AUTOSAR XML (schema 4-2-2)
package /AUTOSAR_ComM/SwcImplementations
  swc implementation ComM_Imp: programming-language=C, sw-version=10.0.0, vendor-id=6, behavior=ComM_Int
    code-descriptors:
      code ComM_Imp_Code: artifact-descriptors=autosar-engineering-object={short-label=Code, category=SWSRC}
    resource consumption ResourceConsumption_ResourceConsumption
package /AUTOSAR_ComM/SwComponentTypes
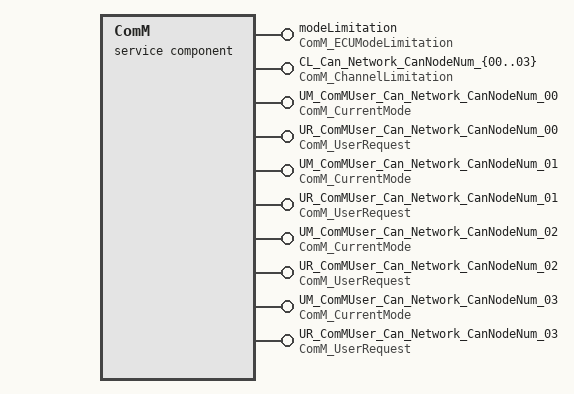
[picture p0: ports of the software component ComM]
  service sw component type ComM
    13 x provide port:
      modeLimitation: provided-interface=ComM_ECUModeLimitation
      CL_Can_Network_CanNodeNum_{00..03}: provided-interface=ComM_ChannelLimitation
      UM_ComMUser_Can_Network_CanNodeNum_00: mode-switch-sender-com-spec{mode-group=currentMode, queue-length=1}, provided-interface=ComM_CurrentMode
      UR_ComMUser_Can_Network_CanNodeNum_00: server-com-spec{operation=RequestComMode, queue-length=5}, provided-interface=ComM_UserRequest
      UM_ComMUser_Can_Network_CanNodeNum_01: mode-switch-sender-com-spec{mode-group=currentMode, queue-length=1}, provided-interface=ComM_CurrentMode
      UR_ComMUser_Can_Network_CanNodeNum_01: server-com-spec{operation=RequestComMode, queue-length=5}, provided-interface=ComM_UserRequest
      UM_ComMUser_Can_Network_CanNodeNum_02: mode-switch-sender-com-spec{mode-group=currentMode, queue-length=1}, provided-interface=ComM_CurrentMode
      UR_ComMUser_Can_Network_CanNodeNum_02: server-com-spec{operation=RequestComMode, queue-length=5}, provided-interface=ComM_UserRequest
      UM_ComMUser_Can_Network_CanNodeNum_03: mode-switch-sender-com-spec{mode-group=currentMode, queue-length=1}, provided-interface=ComM_CurrentMode
      UR_ComMUser_Can_Network_CanNodeNum_03: server-com-spec{operation=RequestComMode, queue-length=5}, provided-interface=ComM_UserRequest
    behavior ComM_Int: data-type-mapping=ComMModeMapping, handle-termination-and-restart=CAN-BE-TERMINATED-AND-RESTARTED
      28 x operation invoked event:
        OIE_UR_ComMUser_Can_Network_CanNodeNum_00_RequestComMode: start-on-event=RequestComMode, operation=UR_ComMUser_Can_Network_CanNodeNum_00.RequestComMode
        OIE_UR_ComMUser_Can_Network_CanNodeNum_00_GetRequestedComMode: start-on-event=GetRequestedComMode, operation=UR_ComMUser_Can_Network_CanNodeNum_00.GetRequestedComMode
        OIE_UR_ComMUser_Can_Network_CanNodeNum_00_GetCurrentComMode: start-on-event=GetCurrentComMode, operation=UR_ComMUser_Can_Network_CanNodeNum_00.GetCurrentComMode
        OIE_UR_ComMUser_Can_Network_CanNodeNum_00_GetMaxComMode: start-on-event=GetMaxComMode, operation=UR_ComMUser_Can_Network_CanNodeNum_00.GetMaxComMode
        OIE_UR_ComMUser_Can_Network_CanNodeNum_01_RequestComMode: start-on-event=RequestComMode, operation=UR_ComMUser_Can_Network_CanNodeNum_01.RequestComMode
        OIE_UR_ComMUser_Can_Network_CanNodeNum_01_GetRequestedComMode: start-on-event=GetRequestedComMode, operation=UR_ComMUser_Can_Network_CanNodeNum_01.GetRequestedComMode
        OIE_UR_ComMUser_Can_Network_CanNodeNum_01_GetCurrentComMode: start-on-event=GetCurrentComMode, operation=UR_ComMUser_Can_Network_CanNodeNum_01.GetCurrentComMode
        OIE_UR_ComMUser_Can_Network_CanNodeNum_01_GetMaxComMode: start-on-event=GetMaxComMode, operation=UR_ComMUser_Can_Network_CanNodeNum_01.GetMaxComMode
        OIE_UR_ComMUser_Can_Network_CanNodeNum_02_RequestComMode: start-on-event=RequestComMode, operation=UR_ComMUser_Can_Network_CanNodeNum_02.RequestComMode
        OIE_UR_ComMUser_Can_Network_CanNodeNum_02_GetRequestedComMode: start-on-event=GetRequestedComMode, operation=UR_ComMUser_Can_Network_CanNodeNum_02.GetRequestedComMode
        OIE_UR_ComMUser_Can_Network_CanNodeNum_02_GetCurrentComMode: start-on-event=GetCurrentComMode, operation=UR_ComMUser_Can_Network_CanNodeNum_02.GetCurrentComMode
        OIE_UR_ComMUser_Can_Network_CanNodeNum_02_GetMaxComMode: start-on-event=GetMaxComMode, operation=UR_ComMUser_Can_Network_CanNodeNum_02.GetMaxComMode
        OIE_UR_ComMUser_Can_Network_CanNodeNum_03_RequestComMode: start-on-event=RequestComMode, operation=UR_ComMUser_Can_Network_CanNodeNum_03.RequestComMode
        OIE_UR_ComMUser_Can_Network_CanNodeNum_03_GetRequestedComMode: start-on-event=GetRequestedComMode, operation=UR_ComMUser_Can_Network_CanNodeNum_03.GetRequestedComMode
        OIE_UR_ComMUser_Can_Network_CanNodeNum_03_GetCurrentComMode: start-on-event=GetCurrentComMode, operation=UR_ComMUser_Can_Network_CanNodeNum_03.GetCurrentComMode
        OIE_UR_ComMUser_Can_Network_CanNodeNum_03_GetMaxComMode: start-on-event=GetMaxComMode, operation=UR_ComMUser_Can_Network_CanNodeNum_03.GetMaxComMode
        OIE_ML_LimitECUToNoComMode: start-on-event=LimitECUToNoComMode, operation=modeLimitation.LimitECUToNoComMode
        OIE_ML_ReadInhibitCounter: start-on-event=ReadInhibitCounter, operation=modeLimitation.ReadInhibitCounter
        OIE_ML_ResetInhibitCounter: start-on-event=ResetInhibitCounter, operation=modeLimitation.ResetInhibitCounter
        OIE_ML_SetECUGroupClassification: start-on-event=SetECUGroupClassification, operation=modeLimitation.SetECUGroupClassification
        OIE_CL_Can_Network_CanNodeNum_00_LimitChannelToNoComMode: start-on-event=LimitChannelToNoComMode, operation=CL_Can_Network_CanNodeNum_00.LimitChannelToNoComMode
        OIE_CL_Can_Network_CanNodeNum_00_GetInhibitionStatus: start-on-event=GetInhibitionStatus, operation=CL_Can_Network_CanNodeNum_00.GetInhibitionStatus
        OIE_CL_Can_Network_CanNodeNum_01_LimitChannelToNoComMode: start-on-event=LimitChannelToNoComMode, operation=CL_Can_Network_CanNodeNum_01.LimitChannelToNoComMode
        OIE_CL_Can_Network_CanNodeNum_01_GetInhibitionStatus: start-on-event=GetInhibitionStatus, operation=CL_Can_Network_CanNodeNum_01.GetInhibitionStatus
        OIE_CL_Can_Network_CanNodeNum_02_LimitChannelToNoComMode: start-on-event=LimitChannelToNoComMode, operation=CL_Can_Network_CanNodeNum_02.LimitChannelToNoComMode
        OIE_CL_Can_Network_CanNodeNum_02_GetInhibitionStatus: start-on-event=GetInhibitionStatus, operation=CL_Can_Network_CanNodeNum_02.GetInhibitionStatus
        OIE_CL_Can_Network_CanNodeNum_03_LimitChannelToNoComMode: start-on-event=LimitChannelToNoComMode, operation=CL_Can_Network_CanNodeNum_03.LimitChannelToNoComMode
        OIE_CL_Can_Network_CanNodeNum_03_GetInhibitionStatus: start-on-event=GetInhibitionStatus, operation=CL_Can_Network_CanNodeNum_03.GetInhibitionStatus
      port-api-options:
        {enable-take-address=false, indirect-api=false, port-defined-argument-value{value=UR_ComMUser_Can_Network_CanNodeNum_00:0, value-type=ComM_UserHandleType}, port=UR_ComMUser_Can_Network_CanNodeNum_00}
        {enable-take-address=false, indirect-api=false, port-defined-argument-value{value=UR_ComMUser_Can_Network_CanNodeNum_01:1, value-type=ComM_UserHandleType}, port=UR_ComMUser_Can_Network_CanNodeNum_01}
        {enable-take-address=false, indirect-api=false, port-defined-argument-value{value=UR_ComMUser_Can_Network_CanNodeNum_02:2, value-type=ComM_UserHandleType}, port=UR_ComMUser_Can_Network_CanNodeNum_02}
        {enable-take-address=false, indirect-api=false, port-defined-argument-value{value=UR_ComMUser_Can_Network_CanNodeNum_03:3, value-type=ComM_UserHandleType}, port=UR_ComMUser_Can_Network_CanNodeNum_03}
        {enable-take-address=false, indirect-api=false, port-defined-argument-value{value=CL_Can_Network_CanNodeNum_00:0, value-type=NetworkHandleType}, port=CL_Can_Network_CanNodeNum_00}
        {enable-take-address=false, indirect-api=false, port-defined-argument-value{value=CL_Can_Network_CanNodeNum_01:1, value-type=NetworkHandleType}, port=CL_Can_Network_CanNodeNum_01}
        {enable-take-address=false, indirect-api=false, port-defined-argument-value{value=CL_Can_Network_CanNodeNum_02:2, value-type=NetworkHandleType}, port=CL_Can_Network_CanNodeNum_02}
        {enable-take-address=false, indirect-api=false, port-defined-argument-value{value=CL_Can_Network_CanNodeNum_03:3, value-type=NetworkHandleType}, port=CL_Can_Network_CanNodeNum_03}
      14 x runnable:
        LimitECUToNoComMode: runnable-entity-argument=symbol=Status, symbol=ComM_LimitECUToNoComMode
        ReadInhibitCounter: runnable-entity-argument=symbol=CounterValue, symbol=ComM_ReadInhibitCounter
        ResetInhibitCounter: symbol=ComM_ResetInhibitCounter
        SetECUGroupClassification: runnable-entity-argument=symbol=Status, symbol=ComM_SetECUGroupClassification
        LimitChannelToNoComMode: arguments=[symbol=Channel, symbol=Status], symbol=ComM_LimitChannelToNoComMode
        GetInhibitionStatus: arguments=[symbol=Channel, symbol=Status], symbol=ComM_GetInhibitionStatus
        RequestComMode: arguments=[symbol=User, symbol=ComMode], can-be-invoked-concurrently=true, symbol=ComM_RequestComMode
        MainFunction_Can_Network_CanNodeNum_{00..03}: symbol=ComM_MainFunction_Can_Network_CanNodeNum_{00..03}
        GetMaxComMode: arguments=[symbol=User, symbol=ComMode], can-be-invoked-concurrently=true, symbol=ComM_GetMaxComMode
        GetRequestedComMode: arguments=[symbol=User, symbol=ComMode], can-be-invoked-concurrently=true, symbol=ComM_GetRequestedComMode
        GetCurrentComMode: arguments=[symbol=User, symbol=ComMode], can-be-invoked-concurrently=true, symbol=ComM_GetCurrentComMode
          4 x mode switch point:
            MSP_ComM_User_ComMUser_Can_Network_CanNodeNum_{00..03}: mode-group=UM_ComMUser_Can_Network_CanNodeNum_{00..03}.currentMode
package /AUTOSAR_ComM/SwcBswMappings/SwcBswmapping
  swc bsw mapping SwcBswMapping_ComM: bsw-behavior=BswInternalBehavior, swc-behavior=ComM_Int
    runnable-mappings:
      bsw-entity=SE_MainFunction_Can_Network_CanNodeNum_{00..03}, swc-runnable=MainFunction_Can_Network_CanNodeNum_{00..03}
